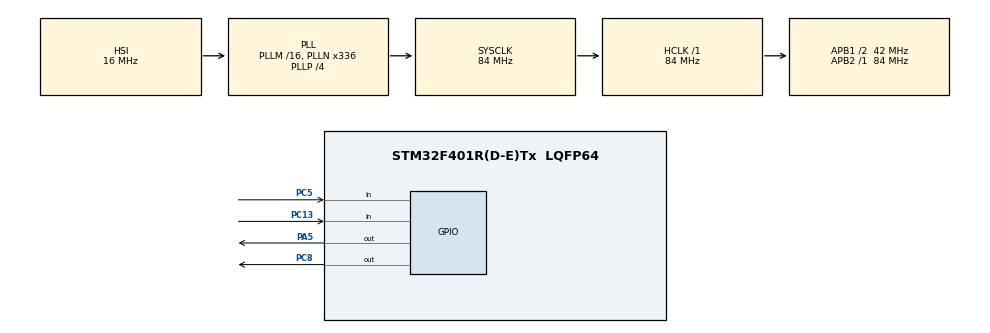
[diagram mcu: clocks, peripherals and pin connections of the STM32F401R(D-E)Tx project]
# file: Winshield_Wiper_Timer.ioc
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Mcu.Family=STM32F4
Mcu.Name=STM32F401R(D-E)Tx
Mcu.Package=LQFP64
NVIC.PriorityGroup=NVIC_PRIORITYGROUP_0
PA13.Mode=Serial_Wire
PA13.Signal=SYS_JTMS-SWDIO
PA14.Mode=Serial_Wire
PA14.Signal=SYS_JTCK-SWCLK
PA5.Signal=GPIO_Output
PC13-ANTI_TAMP.Signal=GPIO_Input
PC5.Signal=GPIO_Input
PC8.Signal=GPIO_Output
PH0\ -\ OSC_IN.Mode=HSE-External-Oscillator
PH0\ -\ OSC_IN.Signal=RCC_OSC_IN
PH1\ -\ OSC_OUT.Mode=HSE-External-Oscillator
PH1\ -\ OSC_OUT.Signal=RCC_OSC_OUT
ProjectManager.HeapSize=0x200
ProjectManager.StackSize=0x400
ProjectManager.TargetToolchain=EWARM
RCC.AHBFreq_Value=84000000
RCC.APB1CLKDivider=RCC_HCLK_DIV2
RCC.APB1Freq_Value=42000000
RCC.APB1TimFreq_Value=84000000
RCC.APB2Freq_Value=84000000
RCC.APB2TimFreq_Value=84000000
RCC.CortexFreq_Value=84000000
RCC.HCLKFreq_Value=84000000
RCC.HSE_VALUE=8000000
RCC.HSI_VALUE=16000000
RCC.LSE_VALUE=32768
RCC.PLLN=336
RCC.PLLP=RCC_PLLP_DIV4
RCC.PLLQ=7
RCC.SYSCLKFreq_VALUE=84000000
RCC.SYSCLKSource=RCC_SYSCLKSOURCE_PLLCLK
RCC.VCOOutputFreq_Value=336000000
VP_TIM2_VS_ClockSourceINT.Mode=Internal
VP_TIM2_VS_ClockSourceITR.Mode=TriggerSource_ITR0
board=NUCLEO-F401RE

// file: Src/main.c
/**
  ******************************************************************************
  * File Name          : main.c
  * Description        : Main program body
  ******************************************************************************
  ** This notice applies to any and all portions of this file
  * that are not between comment pairs USER CODE BEGIN and
  * USER CODE END. Other portions of this file, whether
  * inserted by the user or by software development tools
  * are owned by their respective copyright owners.
  *
  * COPYRIGHT(c) 2017 STMicroelectronics
  *
  * Redistribution and use in source and binary forms, with or without modification,
  * are permitted provided that the following conditions are met:
  *   1. Redistributions of source code must retain the above copyright notice,
  *      this list of conditions and the following disclaimer.
  *   2. Redistributions in binary form must reproduce the above copyright notice,
  *      this list of conditions and the following disclaimer in the documentation
  *      and/or other materials provided with the distribution.
  *   3. Neither the name of STMicroelectronics nor the names of its contributors
  *      may be used to endorse or promote products derived from this software
  *      without specific prior written permission.
  *
  * THIS SOFTWARE IS PROVIDED BY THE COPYRIGHT HOLDERS AND CONTRIBUTORS "AS IS"
  * AND ANY EXPRESS OR IMPLIED WARRANTIES, INCLUDING, BUT NOT LIMITED TO, THE
  * IMPLIED WARRANTIES OF MERCHANTABILITY AND FITNESS FOR A PARTICULAR PURPOSE ARE
  * DISCLAIMED. IN NO EVENT SHALL THE COPYRIGHT HOLDER OR CONTRIBUTORS BE LIABLE
  * FOR ANY DIRECT, INDIRECT, INCIDENTAL, SPECIAL, EXEMPLARY, OR CONSEQUENTIAL
  * DAMAGES (INCLUDING, BUT NOT LIMITED TO, PROCUREMENT OF SUBSTITUTE GOODS OR
  * SERVICES; LOSS OF USE, DATA, OR PROFITS; OR BUSINESS INTERRUPTION) HOWEVER
  * CAUSED AND ON ANY THEORY OF LIABILITY, WHETHER IN CONTRACT, STRICT LIABILITY,
  * OR TORT (INCLUDING NEGLIGENCE OR OTHERWISE) ARISING IN ANY WAY OUT OF THE USE
  * OF THIS SOFTWARE, EVEN IF ADVISED OF THE POSSIBILITY OF SUCH DAMAGE.
  *
  ******************************************************************************
  */

#include "main.h"
#include "stm32f4xx_hal.h"
/* USER CODE BEGIN Includes */

// Test where new headers will go
#include "wiper_functions.h"
#include "wiper_functions.c"

/* USER CODE END Includes */

TIM_HandleTypeDef htim2;

/* USER CODE BEGIN PV */
/* Private variables ---------------------------------------------------------*/

/* USER CODE END PV */

void SystemClock_Config(void);
static void MX_GPIO_Init(void);
static void MX_TIM2_Init(void);

/* USER CODE BEGIN PFP */
void On_When_Pushed(void);
/* Private function prototypes -----------------------------------------------*/

/* USER CODE END PFP */

int main(void)
{

  /* USER CODE BEGIN 1 */
  uint32_t blink_time = 0;
  /* USER CODE END 1 */

  /* MCU Configuration----------------------------------------------------------*/

  /* Reset of all peripherals, Initializes the Flash interface and the Systick. */
  HAL_Init();

  /* Configure the system clock */
  SystemClock_Config();

  /* Initialize all configured peripherals */
  MX_GPIO_Init();
  MX_TIM2_Init();

  /* Infinite loop */
  while (1)
  {
  /* USER CODE BEGIN 3 */
//blink_time defined above
    if (Button_Pressed){
      blink_time = Get_Time();
    }
    else{
      Blink_Timed(blink_time);
    }
  // On_When_Pushed();
  /* USER CODE END 3 */
}
}
/** System Clock Configuration
*/
void SystemClock_Config(void)
{

  RCC_OscInitTypeDef RCC_OscInitStruct;
  RCC_ClkInitTypeDef RCC_ClkInitStruct;

    /**Configure the main internal regulator output voltage
    */
  __HAL_RCC_PWR_CLK_ENABLE();

  __HAL_PWR_VOLTAGESCALING_CONFIG(PWR_REGULATOR_VOLTAGE_SCALE2);

    /**Initializes the CPU, AHB and APB busses clocks
    */
  RCC_OscInitStruct.OscillatorType = RCC_OSCILLATORTYPE_HSI;
  RCC_OscInitStruct.HSIState = RCC_HSI_ON;
  RCC_OscInitStruct.HSICalibrationValue = 16;
  RCC_OscInitStruct.PLL.PLLState = RCC_PLL_ON;
  RCC_OscInitStruct.PLL.PLLSource = RCC_PLLSOURCE_HSI;
  RCC_OscInitStruct.PLL.PLLM = 16;
  RCC_OscInitStruct.PLL.PLLN = 336;
  RCC_OscInitStruct.PLL.PLLP = RCC_PLLP_DIV4;
  RCC_OscInitStruct.PLL.PLLQ = 7;
  if (HAL_RCC_OscConfig(&RCC_OscInitStruct) != HAL_OK)
  {
    _Error_Handler(__FILE__, __LINE__);
  }

    /**Initializes the CPU, AHB and APB busses clocks
    */
  RCC_ClkInitStruct.ClockType = RCC_CLOCKTYPE_HCLK|RCC_CLOCKTYPE_SYSCLK
                              |RCC_CLOCKTYPE_PCLK1|RCC_CLOCKTYPE_PCLK2;
  RCC_ClkInitStruct.SYSCLKSource = RCC_SYSCLKSOURCE_PLLCLK;
  RCC_ClkInitStruct.AHBCLKDivider = RCC_SYSCLK_DIV1;
  RCC_ClkInitStruct.APB1CLKDivider = RCC_HCLK_DIV2;
  RCC_ClkInitStruct.APB2CLKDivider = RCC_HCLK_DIV1;

  if (HAL_RCC_ClockConfig(&RCC_ClkInitStruct, FLASH_LATENCY_2) != HAL_OK)
  {
    _Error_Handler(__FILE__, __LINE__);
  }

    /**Configure the Systick interrupt time
    */
  HAL_SYSTICK_Config(HAL_RCC_GetHCLKFreq()/1000);

    /**Configure the Systick
    */
  HAL_SYSTICK_CLKSourceConfig(SYSTICK_CLKSOURCE_HCLK);

  /* SysTick_IRQn interrupt configuration */
  HAL_NVIC_SetPriority(SysTick_IRQn, 0, 0);
}

/* TIM2 init function */
static void MX_TIM2_Init(void)
{

  TIM_ClockConfigTypeDef sClockSourceConfig;
  TIM_SlaveConfigTypeDef sSlaveConfig;
  TIM_MasterConfigTypeDef sMasterConfig;

  htim2.Instance = TIM2;
  htim2.Init.Prescaler = 0;
  htim2.Init.CounterMode = TIM_COUNTERMODE_UP;
  htim2.Init.Period = 0;
  htim2.Init.ClockDivision = TIM_CLOCKDIVISION_DIV1;
  if (HAL_TIM_Base_Init(&htim2) != HAL_OK)
  {
    _Error_Handler(__FILE__, __LINE__);
  }

  sClockSourceConfig.ClockSource = TIM_CLOCKSOURCE_INTERNAL;
  if (HAL_TIM_ConfigClockSource(&htim2, &sClockSourceConfig) != HAL_OK)
  {
    _Error_Handler(__FILE__, __LINE__);
  }

  sSlaveConfig.SlaveMode = TIM_SLAVEMODE_DISABLE;
  sSlaveConfig.InputTrigger = TIM_TS_ITR0;
  if (HAL_TIM_SlaveConfigSynchronization(&htim2, &sSlaveConfig) != HAL_OK)
  {
    _Error_Handler(__FILE__, __LINE__);
  }

  sMasterConfig.MasterOutputTrigger = TIM_TRGO_RESET;
  sMasterConfig.MasterSlaveMode = TIM_MASTERSLAVEMODE_DISABLE;
  if (HAL_TIMEx_MasterConfigSynchronization(&htim2, &sMasterConfig) != HAL_OK)
  {
    _Error_Handler(__FILE__, __LINE__);
  }

}

/** Configure pins as
        * Analog
        * Input
        * Output
        * EVENT_OUT
        * EXTI
*/
static void MX_GPIO_Init(void)
{

  GPIO_InitTypeDef GPIO_InitStruct;

  /* GPIO Ports Clock Enable */
  __HAL_RCC_GPIOC_CLK_ENABLE();
  __HAL_RCC_GPIOH_CLK_ENABLE();
  __HAL_RCC_GPIOA_CLK_ENABLE();

  /*Configure GPIO pin Output Level */
  HAL_GPIO_WritePin(GPIOA, GPIO_PIN_5, GPIO_PIN_RESET);

  /*Configure GPIO pin Output Level */
  HAL_GPIO_WritePin(GPIOC, GPIO_PIN_8, GPIO_PIN_RESET);

  /*Configure GPIO pins : PC13 PC5 */
  GPIO_InitStruct.Pin = GPIO_PIN_13|GPIO_PIN_5;
  GPIO_InitStruct.Mode = GPIO_MODE_INPUT;
  GPIO_InitStruct.Pull = GPIO_NOPULL;
  HAL_GPIO_Init(GPIOC, &GPIO_InitStruct);

  /*Configure GPIO pin : PA5 */
  GPIO_InitStruct.Pin = GPIO_PIN_5;
  GPIO_InitStruct.Mode = GPIO_MODE_OUTPUT_PP;
  GPIO_InitStruct.Pull = GPIO_NOPULL;
  GPIO_InitStruct.Speed = GPIO_SPEED_FREQ_LOW;
  HAL_GPIO_Init(GPIOA, &GPIO_InitStruct);

  /*Configure GPIO pin : PC8 */
  GPIO_InitStruct.Pin = GPIO_PIN_8;
  GPIO_InitStruct.Mode = GPIO_MODE_OUTPUT_PP;
  GPIO_InitStruct.Pull = GPIO_NOPULL;
  GPIO_InitStruct.Speed = GPIO_SPEED_FREQ_LOW;
  HAL_GPIO_Init(GPIOC, &GPIO_InitStruct);

}

void _Error_Handler(char * file, int line)
{
  while(1)
  {
  }
}

/************************ (C) COPYRIGHT STMicroelectronics *****END OF FILE****/
